# STM32H743 register map
File version: 2.4
CPU: CM7 r0p1, little endian, MPU, FPU, 4 interrupt priority bits
Registers are 32-bit, read-write, reset 0x0 unless marked. A register's access mark holds for its fields unless they carry their own. Offsets are from the block's base; [hi:lo] are bit positions.

## DAC — 数模转换器（DAC）
Base 0x40007400
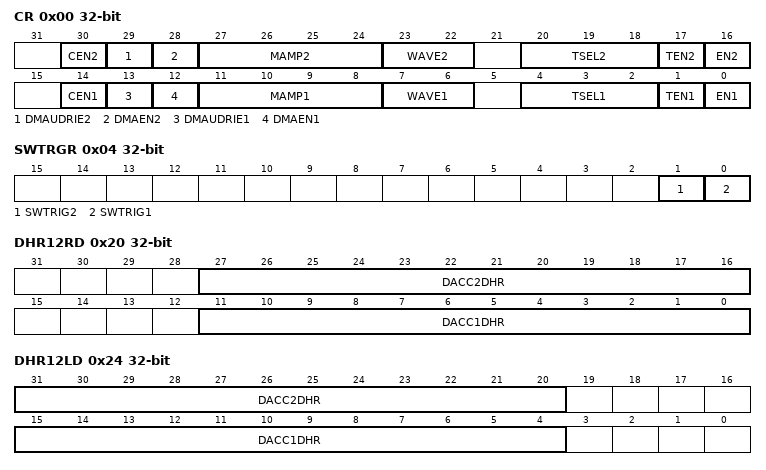
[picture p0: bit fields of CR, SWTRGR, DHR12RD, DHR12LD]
0x00 CR — DAC 控制寄存器
  [30] CEN2 — DAC 通道 2 校准使能位。此位由软件置位或清零，用于使能或禁用 DAC 通道 2 校准。仅当 DAC_CR 寄存器中 EN2 位 = 0 时才能写入（仅当 DAC 通道禁用时方可进入或退出校准模式）。否则，写操作将被忽略。
  [29] DMAUDRIE2 — DAC 通道 2 DMA 欠载中断使能位。此位由软件置位或清零。
  [28] DMAEN2 — DAC 通道 2 DMA 使能位。此位由软件置位或清零。
  [27:24] MAMP2 — DAC 通道 2 屏蔽/幅值选择位。这些位由软件写入，用于在波形生成模式下选择 LFSR 屏蔽位，或在三角波生成模式下选择幅值。= 1011：不屏蔽 LFSR 的位[11:0] / 三角波幅值等于 4095。
  [23:22] WAVE2 — DAC 通道 2 噪声/三角波生成使能位。这些位由软件置位或复位。1x：使能三角波生成。注意：仅当 TEN2 位 = 1（DAC 通道 2 触发使能）时有效。
  [20:18] TSEL2 — DAC 通道 2 触发源选择位。这些位用于选择触发 DAC 通道 2 的外部事件。注意：仅当 TEN2 位 = 1（DAC 通道 2 触发使能）时有效。
  [17] TEN2 — DAC 通道 2 触发使能位。
  [16] EN2 — DAC 通道 2 使能位。此位由软件置位或清零，用于使能或禁用 DAC 通道 2。
  [14] CEN1 — DAC 通道 1 校准使能位。此位由软件置位或清零，用于使能或禁用 DAC 通道 1 校准。仅当 DAC_CR 寄存器中 EN1 位 = 0 时才能写入（仅当 DAC 通道禁用时方可进入或退出校准模式）。否则，写操作将被忽略。
  [13] DMAUDRIE1 — DAC 通道 1 DMA 欠载中断使能位。此位由软件置位或清零。
  [12] DMAEN1 — DAC 通道 1 DMA 使能位。此位由软件置位或清零。
  [11:8] MAMP1 — DAC 通道 1 屏蔽/幅值选择位。这些位由软件写入，用于在波形生成模式下选择 LFSR 屏蔽位，或在三角波生成模式下选择幅值。= 1011：不屏蔽 LFSR 的位[11:0] / 三角波幅值等于 4095。
  [7:6] WAVE1 — DAC 通道 1 噪声/三角波生成使能位。这些位由软件置位或清零。注意：仅当 TEN1 位 = 1（DAC 通道 1 触发使能）时有效。
  [4:2] TSEL1 — DAC 通道 1 触发源选择位。这些位用于选择触发 DAC 通道 1 的外部事件。注意：仅当 TEN1 位 = 1（DAC 通道 1 触发使能）时有效。
  [1] TEN1 — DAC 通道 1 触发使能位。
  [0] EN1 — DAC 通道 1 使能位。此位由软件置位或清零，用于使能或禁用 DAC 通道 1。
0x04 SWTRGR wo — DAC 软件触发寄存器
  [1] SWTRIG2 — DAC 通道 2 软件触发位。此位由软件置位，用于在软件触发模式下触发 DAC。注意：一旦 DAC_DHR2 寄存器的值加载到 DAC_DOR2 寄存器之后，此位由硬件清零（一个 APB1 时钟周期后）。
  [0] SWTRIG1 — DAC 通道 1 软件触发位。此位由软件置位，用于在软件触发模式下触发 DAC。注意：一旦 DAC_DHR1 寄存器的值加载到 DAC_DOR1 寄存器之后，此位由硬件清零（一个 APB1 时钟周期后）。
0x08 DHR12R1 — DAC 通道 1 12 位右对齐数据保持寄存器
  [11:0] DACC1DHR — DAC 通道 1 12 位右对齐数据。这些位由软件写入，指定 DAC 通道 1 的 12 位数据。
0x0C DHR12L1 — DAC 通道 1 12 位左对齐数据保持寄存器
  [15:4] DACC1DHR — DAC 通道 1 12 位左对齐数据。这些位由软件写入，指定 DAC 通道 1 的 12 位数据。
0x10 DHR8R1 — DAC 通道 1 8 位右对齐数据保持寄存器
  [7:0] DACC1DHR — DAC 通道 1 8 位右对齐数据。这些位由软件写入，指定 DAC 通道 1 的 8 位数据。
0x14 DHR12R2 — DAC 通道 2 12 位右对齐数据保持寄存器
  [11:0] DACC2DHR — DAC 通道 2 12 位右对齐数据。这些位由软件写入，指定 DAC 通道 2 的 12 位数据。
0x18 DHR12L2 — DAC 通道 2 12 位左对齐数据保持寄存器
  [15:4] DACC2DHR — DAC 通道 2 12 位左对齐数据。这些位由软件写入，指定 DAC 通道 2 的 12 位数据。
0x1C DHR8R2 — DAC 通道 2 8 位右对齐数据保持寄存器
  [7:0] DACC2DHR — DAC 通道 2 8 位右对齐数据。这些位由软件写入，指定 DAC 通道 2 的 8 位数据。
0x20 DHR12RD — 双 DAC 12 位右对齐数据保持寄存器
  [27:16] DACC2DHR — DAC 通道 2 12 位右对齐数据。这些位由软件写入，指定 DAC 通道 2 的 12 位数据。
  [11:0] DACC1DHR — DAC 通道 1 12 位右对齐数据。这些位由软件写入，指定 DAC 通道 1 的 12 位数据。
0x24 DHR12LD — 双 DAC 12 位左对齐数据保持寄存器
  [31:20] DACC2DHR — DAC 通道 2 12 位左对齐数据。这些位由软件写入，指定 DAC 通道 2 的 12 位数据。
  [15:4] DACC1DHR — DAC 通道 1 12 位左对齐数据。这些位由软件写入，指定 DAC 通道 1 的 12 位数据。
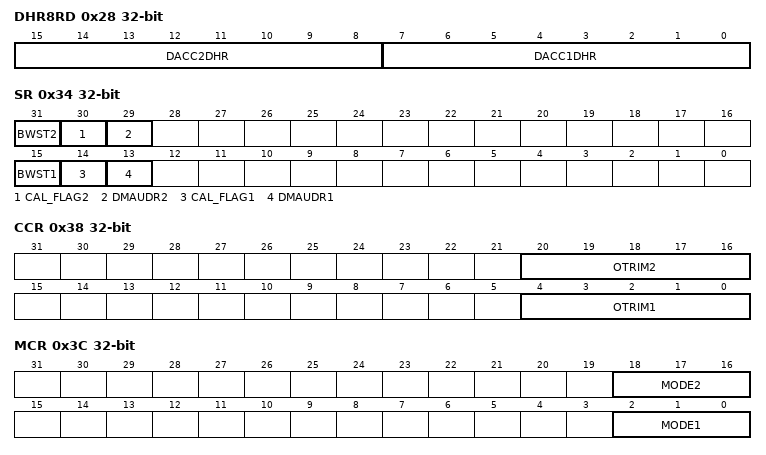
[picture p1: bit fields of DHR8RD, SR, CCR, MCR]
0x28 DHR8RD — 双 DAC 8 位右对齐数据保持寄存器
  [15:8] DACC2DHR — DAC 通道 2 8 位右对齐数据。这些位由软件写入，指定 DAC 通道 2 的 8 位数据。
  [7:0] DACC1DHR — DAC 通道 1 8 位右对齐数据。这些位由软件写入，指定 DAC 通道 1 的 8 位数据。
0x2C DOR1 ro — DAC 通道 1 数据输出寄存器
  [11:0] DACC1DOR — DAC 通道 1 数据输出。这些位为只读，包含 DAC 通道 1 的输出数据。
0x30 DOR2 ro — DAC 通道 2 数据输出寄存器
  [11:0] DACC2DOR — DAC 通道 2 数据输出。这些位为只读，包含 DAC 通道 2 的输出数据。
0x34 SR access per field — DAC 状态寄存器
  [31] BWST2 ro — DAC 通道 2 采样时间写入忙标志位。此位在采样保持模式使能后自动置位，并在每次软件写入 DAC_SHSR2 寄存器时置位。当 DAC_SHSR2 的写操作完成后，由硬件清零（大约需要 3 个 LSI 周期的同步时间）。
  [30] CAL_FLAG2 ro — DAC 通道 2 校准偏移状态位。此位由硬件置位和清零。
  [29] DMAUDR2 rw — DAC 通道 2 DMA 欠载标志位。此位由硬件置位，由软件清零（写入 1 清零）。
  [15] BWST1 ro — DAC 通道 1 采样时间写入忙标志位。此位在采样保持模式使能后自动置位，并在每次软件写入 DAC_SHSR1 寄存器时置位。当 DAC_SHSR1 的写操作完成后，由硬件清零（大约需要 3 个 LSI 周期的同步时间）。
  [14] CAL_FLAG1 ro — DAC 通道 1 校准偏移状态位。此位由硬件置位和清零。
  [13] DMAUDR1 rw — DAC 通道 1 DMA 欠载标志位。此位由硬件置位，由软件清零（写入 1 清零）。
0x38 CCR — DAC 校准控制寄存器
  [20:16] OTRIM2 — DAC 通道 2 偏移微调值。
  [4:0] OTRIM1 — DAC 通道 1 偏移微调值。
0x3C MCR — DAC 模式控制寄存器
  [18:16] MODE2 — DAC 通道 2 模式选择位。这些位仅在 DAC 禁用且未处于校准模式时（即 DAC_CR 寄存器中 EN2 位 = 0 且 CEN2 位 = 0）才能写入。若 EN2 = 1 或 CEN2 = 1，写操作将被忽略。可由软件置位或清零以选择 DAC 通道 2 的工作模式：DAC 通道 2 正常模式，DAC 通道 2 采样保持模式。
  [2:0] MODE1 — DAC 通道 1 模式选择位。这些位仅在 DAC 禁用且未处于校准模式时（即 DAC_CR 寄存器中 EN1 位 = 0 且 CEN1 位 = 0）才能写入。若 EN1 = 1 或 CEN1 = 1，写操作将被忽略。可由软件置位或清零以选择 DAC 通道 1 的工作模式：DAC 通道 1 正常模式，DAC 通道 1 采样保持模式。
0x40 SHSR1 — DAC 采样保持采样时间寄存器 1
  [9:0] TSAMPLE1 — DAC 通道 1 采样时间（仅在采样保持模式下有效）。这些位可在 DAC 通道 1 禁用时写入，亦可在正常工作期间写入。对于后者，仅当 DAC_SR 寄存器的 BWSTx 为低电平时才能写入；若 BWSTx = 1，写操作将被忽略。
0x44 SHSR2 — DAC 采样保持采样时间寄存器 2
  [9:0] TSAMPLE2 — DAC 通道 2 采样时间（仅在采样保持模式下有效）。这些位可在 DAC 通道 2 禁用时写入，亦可在正常工作期间写入。对于后者，仅当 DAC_SR 寄存器的 BWSTx 为低电平时才能写入；若 BWSTx = 1，写操作将被忽略。
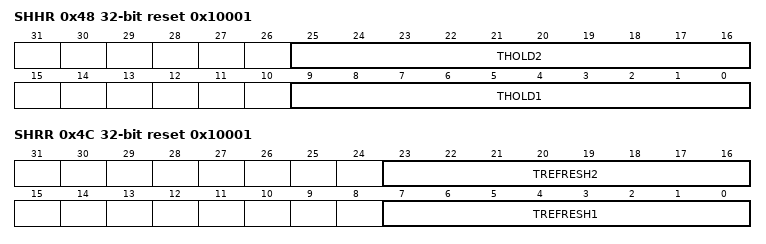
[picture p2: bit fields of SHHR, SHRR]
0x48 SHHR reset 0x10001 — DAC 采样保持保持时间寄存器
  [25:16] THOLD2 — DAC 通道 2 保持时间（仅在采样保持模式下有效）。保持时间 = (THOLD[9:0]) x T_LSI
  [9:0] THOLD1 — DAC 通道 1 保持时间（仅在采样保持模式下有效）。保持时间 = (THOLD[9:0]) x T_LSI
0x4C SHRR reset 0x10001 — DAC 采样保持刷新时间寄存器
  [23:16] TREFRESH2 — DAC 通道 2 刷新时间（仅在采样保持模式下有效）。刷新时间 = (TREFRESH[7:0]) x T_LSI
  [7:0] TREFRESH1 — DAC 通道 1 刷新时间（仅在采样保持模式下有效）。刷新时间 = (TREFRESH[7:0]) x T_LSI
